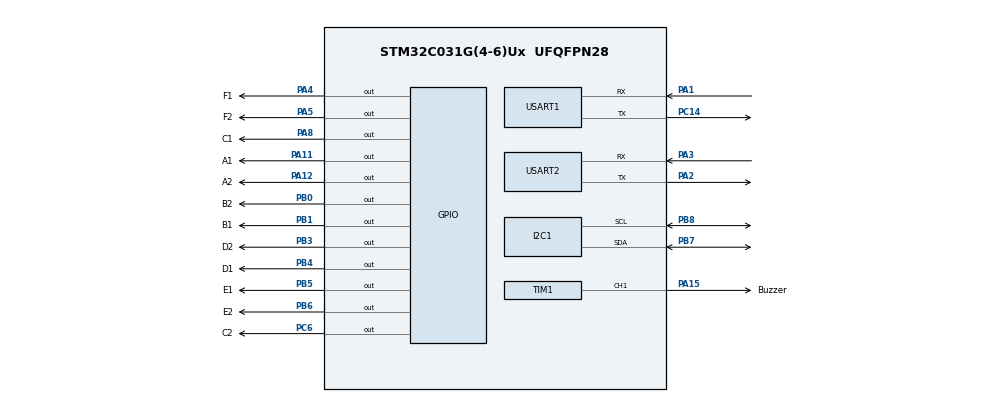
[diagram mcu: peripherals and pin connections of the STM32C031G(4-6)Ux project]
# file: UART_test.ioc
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I2C1.Timing=0x00402D41
Mcu.Family=STM32C0
Mcu.Name=STM32C031G(4-6)Ux
Mcu.Package=UFQFPN28
NVIC.USART1_IRQn=true\:0\:0\:false\:false\:true\:true\:true\:true
NVIC.USART2_IRQn=true\:0\:0\:false\:false\:true\:true\:true\:true
PA1.Mode=Asynchronous
PA1.Signal=USART1_RX
PA11\ [PA9].GPIO_Label=A1
PA11\ [PA9].Signal=GPIO_Output
PA12\ [PA10].GPIO_Label=A2
PA12\ [PA10].Signal=GPIO_Output
PA15.GPIO_Label=Buzzer
PA15.Signal=S_TIM1_CH1
PA2.Mode=Asynchronous
PA2.Signal=USART2_TX
PA3.Mode=Asynchronous
PA3.Signal=USART2_RX
PA4.GPIO_Label=F1
PA4.Signal=GPIO_Output
PA5.GPIO_Label=F2
PA5.Signal=GPIO_Output
PA8.GPIO_Label=C1
PA8.Signal=GPIO_Output
PB0.GPIO_Label=B2
PB0.Signal=GPIO_Output
PB1.GPIO_Label=B1
PB1.Signal=GPIO_Output
PB3.GPIO_Label=D2
PB3.Signal=GPIO_Output
PB4.GPIO_Label=D1
PB4.Signal=GPIO_Output
PB5.GPIO_Label=E1
PB5.Signal=GPIO_Output
PB6.GPIO_Label=E2
PB6.Signal=GPIO_Output
PB7.Mode=I2C
PB7.Signal=I2C1_SDA
PB8.Mode=I2C
PB8.Signal=I2C1_SCL
PC14-OSCX_IN\ (PC14).Mode=Asynchronous
PC14-OSCX_IN\ (PC14).Signal=USART1_TX
PC6.GPIO_Label=C2
PC6.Signal=GPIO_Output
ProjectManager.HeapSize=0x200
ProjectManager.StackSize=0x400
ProjectManager.TargetToolchain=STM32CubeIDE
RCC.ADCFreq_Value=12000000
RCC.AHBFreq_Value=12000000
RCC.CortexFreq_Value=12000000
RCC.EXTERNAL_CLOCK_VALUE=12288000
RCC.HCLKFreq_Value=12000000
RCC.HSE_VALUE=8000000
RCC.HSI_VALUE=48000000
RCC.LSE_VALUE=32768
RCC.SYSCLKFreq_VALUE=12000000
SH.S_TIM1_CH1.0=TIM1_CH1,PWM Generation1 CH1
TIM1.Channel-PWM\ Generation1\ CH1=TIM_CHANNEL_1
TIM1.Period=3000-1
TIM3.Prescaler=48000-1
USART1.VirtualMode-Asynchronous=VM_ASYNC
USART2.VirtualMode-Asynchronous=VM_ASYNC
VP_TIM1_VS_ClockSourceINT.Mode=Internal
VP_TIM3_VS_ClockSourceINT.Mode=Internal
board=custom

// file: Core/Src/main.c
/* USER CODE BEGIN Header */
/**
  ******************************************************************************
  * @file           : main.c
  * @brief          : Main program body
  ******************************************************************************
  * @attention
  *
  * Copyright (c) 2025 STMicroelectronics.
  * All rights reserved.
  *
  * This software is licensed under terms that can be found in the LICENSE file
  * in the root directory of this software component.
  * If no LICENSE file comes with this software, it is provided AS-IS.
  *
  ******************************************************************************
  */
/* USER CODE END Header */
#include "main.h"

/* USER CODE BEGIN Includes */
#include "uart_test.h"
/* USER CODE END Includes */

I2C_HandleTypeDef hi2c1;

TIM_HandleTypeDef htim1;
TIM_HandleTypeDef htim3;

UART_HandleTypeDef huart1;
UART_HandleTypeDef huart2;

UART_TestHandle right_tester;
UART_TestHandle left_tester;

void SystemClock_Config(void);
static void MX_GPIO_Init(void);
static void MX_I2C1_Init(void);
static void MX_TIM1_Init(void);
static void MX_USART1_UART_Init(void);
static void MX_USART2_UART_Init(void);
static void MX_TIM3_Init(void);

int main(void)
{

  /* MCU Configuration--------------------------------------------------------*/

  /* Reset of all peripherals, Initializes the Flash interface and the Systick. */
  HAL_Init();

  /* Configure the system clock */
  SystemClock_Config();

  /* Initialize all configured peripherals */
  MX_GPIO_Init();
  MX_I2C1_Init();
  MX_TIM1_Init();
  MX_USART1_UART_Init();
  MX_USART2_UART_Init();
  MX_TIM3_Init();
  /* USER CODE BEGIN 2 */
  UART_Test_Init(&left_tester, &huart2);
  UART_Test_Init(&right_tester, &huart1);
  /* USER CODE END 2 */

  /* Infinite loop */
  while (1)
  {

  }
}

void SystemClock_Config(void)
{
  RCC_OscInitTypeDef RCC_OscInitStruct = {0};
  RCC_ClkInitTypeDef RCC_ClkInitStruct = {0};

  __HAL_FLASH_SET_LATENCY(FLASH_LATENCY_0);

  /** Initializes the RCC Oscillators according to the specified parameters
  * in the RCC_OscInitTypeDef structure.
  */
  RCC_OscInitStruct.OscillatorType = RCC_OSCILLATORTYPE_HSI;
  RCC_OscInitStruct.HSIState = RCC_HSI_ON;
  RCC_OscInitStruct.HSIDiv = RCC_HSI_DIV4;
  RCC_OscInitStruct.HSICalibrationValue = RCC_HSICALIBRATION_DEFAULT;
  if (HAL_RCC_OscConfig(&RCC_OscInitStruct) != HAL_OK)
  {
    Error_Handler();
  }

  /** Initializes the CPU, AHB and APB buses clocks
  */
  RCC_ClkInitStruct.ClockType = RCC_CLOCKTYPE_HCLK|RCC_CLOCKTYPE_SYSCLK
                              |RCC_CLOCKTYPE_PCLK1;
  RCC_ClkInitStruct.SYSCLKSource = RCC_SYSCLKSOURCE_HSI;
  RCC_ClkInitStruct.SYSCLKDivider = RCC_SYSCLK_DIV1;
  RCC_ClkInitStruct.AHBCLKDivider = RCC_HCLK_DIV1;
  RCC_ClkInitStruct.APB1CLKDivider = RCC_APB1_DIV1;

  if (HAL_RCC_ClockConfig(&RCC_ClkInitStruct, FLASH_LATENCY_0) != HAL_OK)
  {
    Error_Handler();
  }
}

static void MX_I2C1_Init(void)
{

  hi2c1.Instance = I2C1;
  hi2c1.Init.Timing = 0x00402D41;
  hi2c1.Init.OwnAddress1 = 0;
  hi2c1.Init.AddressingMode = I2C_ADDRESSINGMODE_7BIT;
  hi2c1.Init.DualAddressMode = I2C_DUALADDRESS_DISABLE;
  hi2c1.Init.OwnAddress2 = 0;
  hi2c1.Init.OwnAddress2Masks = I2C_OA2_NOMASK;
  hi2c1.Init.GeneralCallMode = I2C_GENERALCALL_DISABLE;
  hi2c1.Init.NoStretchMode = I2C_NOSTRETCH_DISABLE;
  if (HAL_I2C_Init(&hi2c1) != HAL_OK)
  {
    Error_Handler();
  }

  /** Configure Analogue filter
  */
  if (HAL_I2CEx_ConfigAnalogFilter(&hi2c1, I2C_ANALOGFILTER_ENABLE) != HAL_OK)
  {
    Error_Handler();
  }

  /** Configure Digital filter
  */
  if (HAL_I2CEx_ConfigDigitalFilter(&hi2c1, 0) != HAL_OK)
  {
    Error_Handler();
  }

}

static void MX_TIM1_Init(void)
{

  TIM_ClockConfigTypeDef sClockSourceConfig = {0};
  TIM_MasterConfigTypeDef sMasterConfig = {0};
  TIM_OC_InitTypeDef sConfigOC = {0};
  TIM_BreakDeadTimeConfigTypeDef sBreakDeadTimeConfig = {0};

  htim1.Instance = TIM1;
  htim1.Init.Prescaler = 0;
  htim1.Init.CounterMode = TIM_COUNTERMODE_UP;
  htim1.Init.Period = 3000-1;
  htim1.Init.ClockDivision = TIM_CLOCKDIVISION_DIV1;
  htim1.Init.RepetitionCounter = 0;
  htim1.Init.AutoReloadPreload = TIM_AUTORELOAD_PRELOAD_DISABLE;
  if (HAL_TIM_Base_Init(&htim1) != HAL_OK)
  {
    Error_Handler();
  }
  sClockSourceConfig.ClockSource = TIM_CLOCKSOURCE_INTERNAL;
  if (HAL_TIM_ConfigClockSource(&htim1, &sClockSourceConfig) != HAL_OK)
  {
    Error_Handler();
  }
  if (HAL_TIM_PWM_Init(&htim1) != HAL_OK)
  {
    Error_Handler();
  }
  sMasterConfig.MasterOutputTrigger = TIM_TRGO_RESET;
  sMasterConfig.MasterOutputTrigger2 = TIM_TRGO2_RESET;
  sMasterConfig.MasterSlaveMode = TIM_MASTERSLAVEMODE_DISABLE;
  if (HAL_TIMEx_MasterConfigSynchronization(&htim1, &sMasterConfig) != HAL_OK)
  {
    Error_Handler();
  }
  sConfigOC.OCMode = TIM_OCMODE_PWM1;
  sConfigOC.Pulse = 0;
  sConfigOC.OCPolarity = TIM_OCPOLARITY_HIGH;
  sConfigOC.OCNPolarity = TIM_OCNPOLARITY_HIGH;
  sConfigOC.OCFastMode = TIM_OCFAST_DISABLE;
  sConfigOC.OCIdleState = TIM_OCIDLESTATE_RESET;
  sConfigOC.OCNIdleState = TIM_OCNIDLESTATE_RESET;
  if (HAL_TIM_PWM_ConfigChannel(&htim1, &sConfigOC, TIM_CHANNEL_1) != HAL_OK)
  {
    Error_Handler();
  }
  sBreakDeadTimeConfig.OffStateRunMode = TIM_OSSR_DISABLE;
  sBreakDeadTimeConfig.OffStateIDLEMode = TIM_OSSI_DISABLE;
  sBreakDeadTimeConfig.LockLevel = TIM_LOCKLEVEL_OFF;
  sBreakDeadTimeConfig.DeadTime = 0;
  sBreakDeadTimeConfig.BreakState = TIM_BREAK_DISABLE;
  sBreakDeadTimeConfig.BreakPolarity = TIM_BREAKPOLARITY_HIGH;
  sBreakDeadTimeConfig.BreakFilter = 0;
  sBreakDeadTimeConfig.BreakAFMode = TIM_BREAK_AFMODE_INPUT;
  sBreakDeadTimeConfig.Break2State = TIM_BREAK2_DISABLE;
  sBreakDeadTimeConfig.Break2Polarity = TIM_BREAK2POLARITY_HIGH;
  sBreakDeadTimeConfig.Break2Filter = 0;
  sBreakDeadTimeConfig.Break2AFMode = TIM_BREAK_AFMODE_INPUT;
  sBreakDeadTimeConfig.AutomaticOutput = TIM_AUTOMATICOUTPUT_DISABLE;
  if (HAL_TIMEx_ConfigBreakDeadTime(&htim1, &sBreakDeadTimeConfig) != HAL_OK)
  {
    Error_Handler();
  }
  HAL_TIM_MspPostInit(&htim1);

}

static void MX_TIM3_Init(void)
{

  TIM_ClockConfigTypeDef sClockSourceConfig = {0};
  TIM_MasterConfigTypeDef sMasterConfig = {0};

  htim3.Instance = TIM3;
  htim3.Init.Prescaler = 48000-1;
  htim3.Init.CounterMode = TIM_COUNTERMODE_UP;
  htim3.Init.Period = 65535;
  htim3.Init.ClockDivision = TIM_CLOCKDIVISION_DIV1;
  htim3.Init.AutoReloadPreload = TIM_AUTORELOAD_PRELOAD_DISABLE;
  if (HAL_TIM_Base_Init(&htim3) != HAL_OK)
  {
    Error_Handler();
  }
  sClockSourceConfig.ClockSource = TIM_CLOCKSOURCE_INTERNAL;
  if (HAL_TIM_ConfigClockSource(&htim3, &sClockSourceConfig) != HAL_OK)
  {
    Error_Handler();
  }
  sMasterConfig.MasterOutputTrigger = TIM_TRGO_RESET;
  sMasterConfig.MasterSlaveMode = TIM_MASTERSLAVEMODE_DISABLE;
  if (HAL_TIMEx_MasterConfigSynchronization(&htim3, &sMasterConfig) != HAL_OK)
  {
    Error_Handler();
  }

}

static void MX_USART1_UART_Init(void)
{

  huart1.Instance = USART1;
  huart1.Init.BaudRate = 115200;
  huart1.Init.WordLength = UART_WORDLENGTH_8B;
  huart1.Init.StopBits = UART_STOPBITS_1;
  huart1.Init.Parity = UART_PARITY_NONE;
  huart1.Init.Mode = UART_MODE_TX_RX;
  huart1.Init.HwFlowCtl = UART_HWCONTROL_NONE;
  huart1.Init.OverSampling = UART_OVERSAMPLING_16;
  huart1.Init.OneBitSampling = UART_ONE_BIT_SAMPLE_DISABLE;
  huart1.Init.ClockPrescaler = UART_PRESCALER_DIV1;
  huart1.AdvancedInit.AdvFeatureInit = UART_ADVFEATURE_NO_INIT;
  if (HAL_UART_Init(&huart1) != HAL_OK)
  {
    Error_Handler();
  }
  if (HAL_UARTEx_SetTxFifoThreshold(&huart1, UART_TXFIFO_THRESHOLD_1_8) != HAL_OK)
  {
    Error_Handler();
  }
  if (HAL_UARTEx_SetRxFifoThreshold(&huart1, UART_RXFIFO_THRESHOLD_1_8) != HAL_OK)
  {
    Error_Handler();
  }
  if (HAL_UARTEx_DisableFifoMode(&huart1) != HAL_OK)
  {
    Error_Handler();
  }

}

static void MX_USART2_UART_Init(void)
{

  huart2.Instance = USART2;
  huart2.Init.BaudRate = 115200;
  huart2.Init.WordLength = UART_WORDLENGTH_8B;
  huart2.Init.StopBits = UART_STOPBITS_1;
  huart2.Init.Parity = UART_PARITY_NONE;
  huart2.Init.Mode = UART_MODE_TX_RX;
  huart2.Init.HwFlowCtl = UART_HWCONTROL_NONE;
  huart2.Init.OverSampling = UART_OVERSAMPLING_16;
  huart2.Init.OneBitSampling = UART_ONE_BIT_SAMPLE_DISABLE;
  huart2.Init.ClockPrescaler = UART_PRESCALER_DIV1;
  huart2.AdvancedInit.AdvFeatureInit = UART_ADVFEATURE_NO_INIT;
  if (HAL_UART_Init(&huart2) != HAL_OK)
  {
    Error_Handler();
  }

}

static void MX_GPIO_Init(void)
{
  GPIO_InitTypeDef GPIO_InitStruct = {0};

  /* GPIO Ports Clock Enable */
  __HAL_RCC_GPIOC_CLK_ENABLE();
  __HAL_RCC_GPIOA_CLK_ENABLE();
  __HAL_RCC_GPIOB_CLK_ENABLE();

  /*Configure GPIO pin Output Level */
  HAL_GPIO_WritePin(GPIOA, F1_Pin|F2_Pin|C1_Pin|A1_Pin
                          |A2_Pin, GPIO_PIN_RESET);

  /*Configure GPIO pin Output Level */
  HAL_GPIO_WritePin(GPIOB, B2_Pin|B1_Pin|D2_Pin|D1_Pin
                          |E1_Pin|E2_Pin, GPIO_PIN_RESET);

  /*Configure GPIO pin Output Level */
  HAL_GPIO_WritePin(C2_GPIO_Port, C2_Pin, GPIO_PIN_RESET);

  /*Configure GPIO pins : F1_Pin F2_Pin C1_Pin A1_Pin
                           A2_Pin */
  GPIO_InitStruct.Pin = F1_Pin|F2_Pin|C1_Pin|A1_Pin
                          |A2_Pin;
  GPIO_InitStruct.Mode = GPIO_MODE_OUTPUT_PP;
  GPIO_InitStruct.Pull = GPIO_NOPULL;
  GPIO_InitStruct.Speed = GPIO_SPEED_FREQ_LOW;
  HAL_GPIO_Init(GPIOA, &GPIO_InitStruct);

  /*Configure GPIO pins : B2_Pin B1_Pin D2_Pin D1_Pin
                           E1_Pin E2_Pin */
  GPIO_InitStruct.Pin = B2_Pin|B1_Pin|D2_Pin|D1_Pin
                          |E1_Pin|E2_Pin;
  GPIO_InitStruct.Mode = GPIO_MODE_OUTPUT_PP;
  GPIO_InitStruct.Pull = GPIO_NOPULL;
  GPIO_InitStruct.Speed = GPIO_SPEED_FREQ_LOW;
  HAL_GPIO_Init(GPIOB, &GPIO_InitStruct);

  /*Configure GPIO pin : C2_Pin */
  GPIO_InitStruct.Pin = C2_Pin;
  GPIO_InitStruct.Mode = GPIO_MODE_OUTPUT_PP;
  GPIO_InitStruct.Pull = GPIO_NOPULL;
  GPIO_InitStruct.Speed = GPIO_SPEED_FREQ_LOW;
  HAL_GPIO_Init(C2_GPIO_Port, &GPIO_InitStruct);

}

/* USER CODE BEGIN 4 */
void HAL_UART_RxCpltCallback(UART_HandleTypeDef *huart) {
    if (huart == &huart1) UART_Test_RxCallback(&right_tester);
    else if (huart == &huart2) UART_Test_RxCallback(&left_tester);
}
/* USER CODE END 4 */

void Error_Handler(void)
{
  __disable_irq();
  while (1)
  {
  }
}
